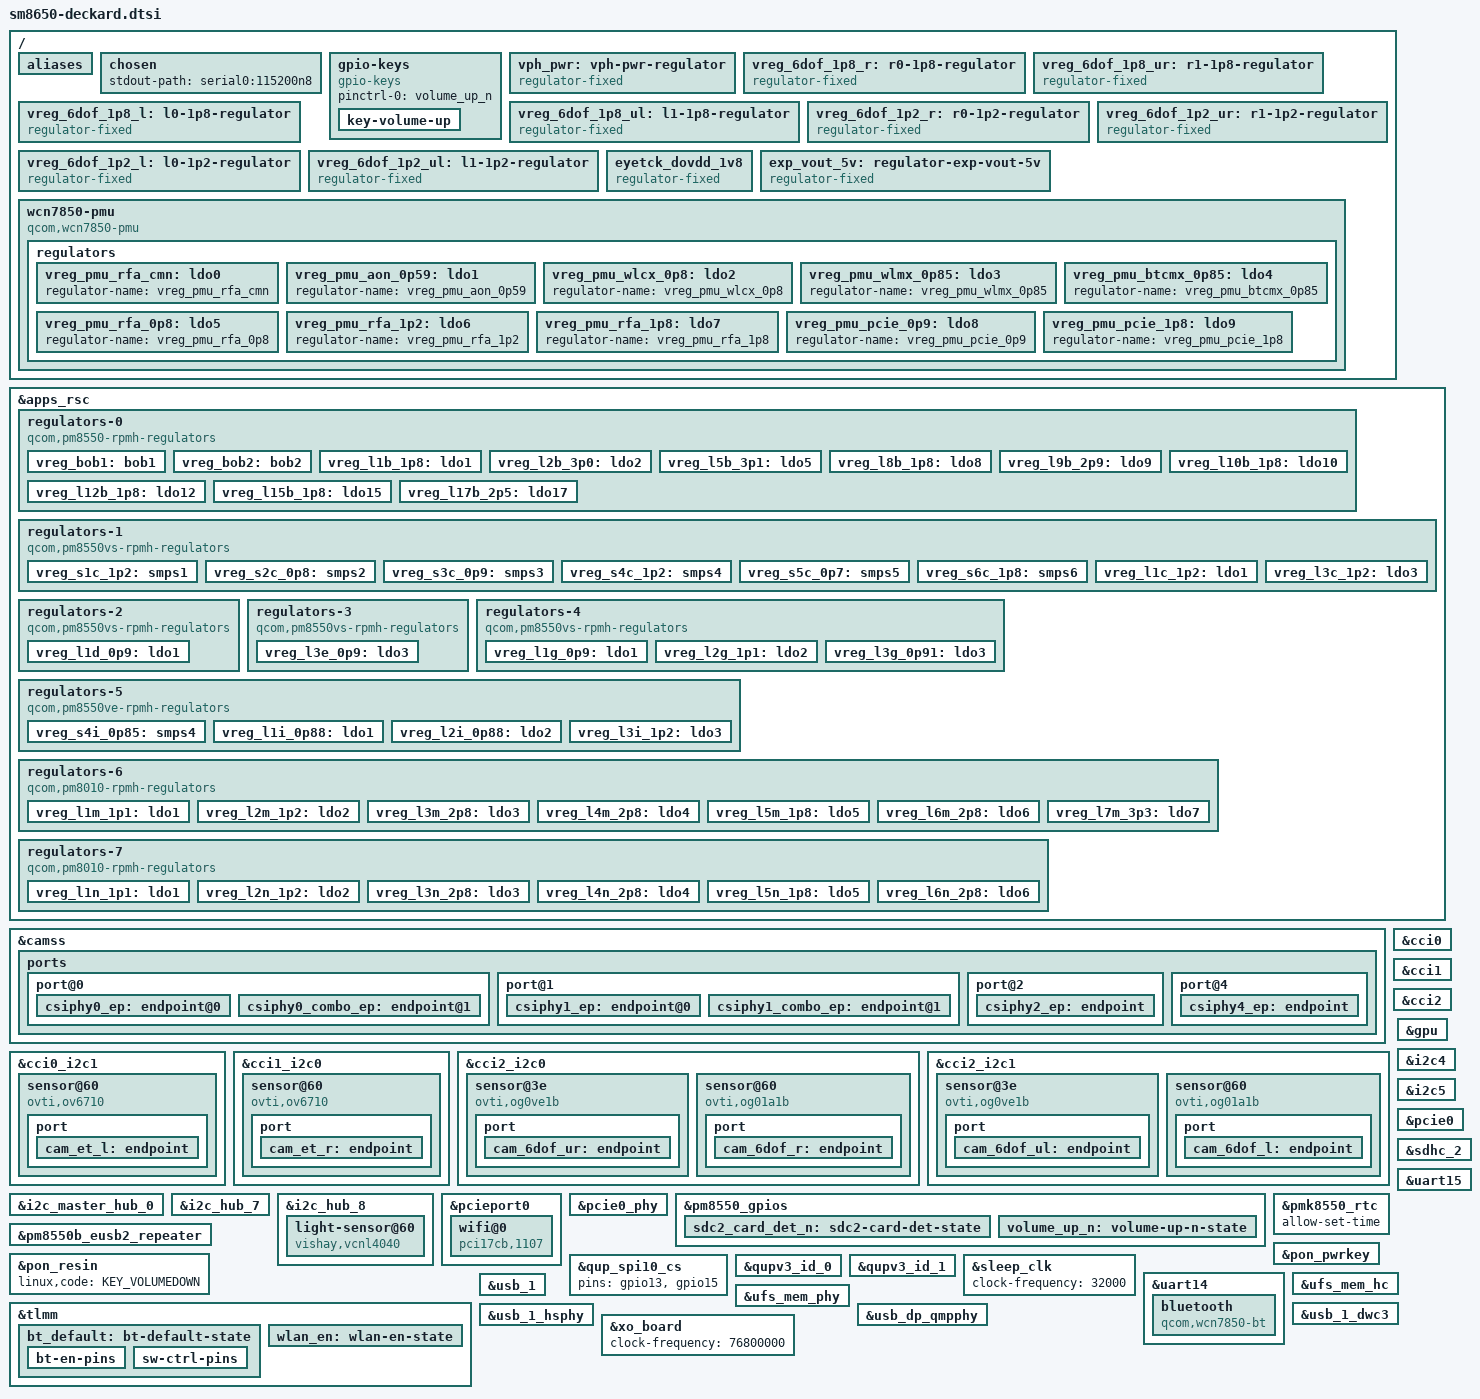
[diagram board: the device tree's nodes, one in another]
#include <dt-bindings/regulator/qcom,rpmh-regulator.h>
#include "sm8650.dtsi"
#include "pm8010.dtsi"
#include "pm8550.dtsi"
#include "pm8550b.dtsi"
#include "pm8550vs.dtsi"
#define PMK8550VE_SID 8
#include "pm8550ve.dtsi"
#include "pmk8550.dtsi"
#include "sm8650-el2.dtsi"

/ {
	aliases {
		serial0 = &uart15;
		serial1 = &uart14;
	};

	chosen {
		stdout-path = "serial0:115200n8";
	};

	gpio-keys {
		compatible = "gpio-keys";

		pinctrl-0 = <&volume_up_n>;
		pinctrl-names = "default";

		key-volume-up {
			label = "Volume Up";
			linux,code = <KEY_VOLUMEUP>;
			gpios = <&pm8550_gpios 6 GPIO_ACTIVE_LOW>;
			debounce-interval = <15>;
			linux,can-disable;
			wakeup-source;
		};
	};

	vph_pwr: vph-pwr-regulator {
		compatible = "regulator-fixed";

		regulator-name = "vph_pwr";
		regulator-min-microvolt = <3700000>;
		regulator-max-microvolt = <3700000>;

		regulator-always-on;
		regulator-boot-on;
	};

	vreg_6dof_1p8_r: r0-1p8-regulator {
		compatible = "regulator-fixed";
		regulator-name = "vreg_6dof_1p8_r";
		regulator-min-microvolt = <1800000>;
		regulator-max-microvolt = <1800000>;
		gpio = <&tlmm 36 GPIO_ACTIVE_HIGH>;
		vin-supply = <&vreg_l5m_1p8>;
		enable-active-high;
	};

	vreg_6dof_1p8_ur: r1-1p8-regulator {
		compatible = "regulator-fixed";
		regulator-name = "vreg_6dof_1p8_ur";
		regulator-min-microvolt = <1800000>;
		regulator-max-microvolt = <1800000>;
		gpio = <&tlmm 33 GPIO_ACTIVE_HIGH>;
		vin-supply = <&vreg_l5m_1p8>;
		enable-active-high;
	};

	vreg_6dof_1p8_l: l0-1p8-regulator {
		compatible = "regulator-fixed";
		regulator-name = "vreg_6dof_1p8_l";
		regulator-min-microvolt = <1800000>;
		regulator-max-microvolt = <1800000>;
		gpio = <&tlmm 36 GPIO_ACTIVE_HIGH>;
		vin-supply = <&vreg_l5n_1p8>;
		enable-active-high;
	};

	vreg_6dof_1p8_ul: l1-1p8-regulator {
		compatible = "regulator-fixed";
		regulator-name = "vreg_6dof_1p8_ul";
		regulator-min-microvolt = <1800000>;
		regulator-max-microvolt = <1800000>;
		gpio = <&tlmm 33 GPIO_ACTIVE_HIGH>;
		vin-supply = <&vreg_l5n_1p8>;
		enable-active-high;
	};

	vreg_6dof_1p2_r: r0-1p2-regulator {
		compatible = "regulator-fixed";
		regulator-name = "vreg_6dof_1p2_r";
		regulator-min-microvolt = <1200000>;
		regulator-max-microvolt = <1200000>;
		gpio = <&tlmm 37 GPIO_ACTIVE_HIGH>;
		vin-supply = <&vreg_l2m_1p2>;
		enable-active-high;
	};

	vreg_6dof_1p2_ur: r1-1p2-regulator {
		compatible = "regulator-fixed";
		regulator-name = "vreg_6dof_1p2_ur";
		regulator-min-microvolt = <1200000>;
		regulator-max-microvolt = <1200000>;
		gpio = <&tlmm 34 GPIO_ACTIVE_HIGH>;
		vin-supply = <&vreg_l2m_1p2>;
		enable-active-high;
	};

	vreg_6dof_1p2_l: l0-1p2-regulator {
		compatible = "regulator-fixed";
		regulator-name = "vreg_6dof_1p2_l";
		regulator-min-microvolt = <1200000>;
		regulator-max-microvolt = <1200000>;
		gpio = <&tlmm 37 GPIO_ACTIVE_HIGH>;
		vin-supply = <&vreg_l2n_1p2>;
		enable-active-high;
	};

	vreg_6dof_1p2_ul: l1-1p2-regulator {
		compatible = "regulator-fixed";
		regulator-name = "vreg_6dof_1p2_ul";
		regulator-min-microvolt = <1200000>;
		regulator-max-microvolt = <1200000>;
		gpio = <&tlmm 34 GPIO_ACTIVE_HIGH>;
		vin-supply = <&vreg_l2n_1p2>;
		enable-active-high;
	};

	eyetck_dovdd_1v8: eyetck_dovdd_1v8 {
		compatible = "regulator-fixed";
		regulator-name = "eyetck_dovdd_1v8";
		regulator-min-microvolt = <1800000>;
		regulator-max-microvolt = <1800000>;
		enable-active-high;
		gpio = <&tlmm 74 GPIO_ACTIVE_HIGH>;
		vin-supply = <&vreg_l5m_1p8>;
	};

	exp_vout_5v: regulator-exp-vout-5v {
		compatible = "regulator-fixed";
		regulator-name = "exp_vout_5v";
		regulator-min-microvolt = <5000000>;
		regulator-max-microvolt = <5000000>;
		gpio = <&pm8550vs_g_gpios 6 GPIO_ACTIVE_HIGH>;
		enable-active-high;
		vin-supply = <&vph_pwr>;
		regulator-always-on;
	};

	wcn7850-pmu {
		compatible = "qcom,wcn7850-pmu";

		pinctrl-names = "default";
		pinctrl-0 = <&wlan_en>, <&bt_default>;

		wlan-enable-gpios = <&tlmm 16 GPIO_ACTIVE_HIGH>;
		bt-enable-gpios = <&tlmm 17 GPIO_ACTIVE_HIGH>;

		vdd-supply = <&vreg_s4i_0p85>;
		vddio-supply = <&vreg_l15b_1p8>;
		vddio1p2-supply = <&vreg_l3c_1p2>;
		vddaon-supply = <&vreg_s2c_0p8>;
		vdddig-supply = <&vreg_s3c_0p9>;
		vddrfa1p2-supply = <&vreg_s1c_1p2>;
		vddrfa1p8-supply = <&vreg_s6c_1p8>;

		clocks = <&rpmhcc RPMH_RF_CLK1>;

		regulators {
			vreg_pmu_rfa_cmn: ldo0 {
				regulator-name = "vreg_pmu_rfa_cmn";
			};

			vreg_pmu_aon_0p59: ldo1 {
				regulator-name = "vreg_pmu_aon_0p59";
			};

			vreg_pmu_wlcx_0p8: ldo2 {
				regulator-name = "vreg_pmu_wlcx_0p8";
			};

			vreg_pmu_wlmx_0p85: ldo3 {
				regulator-name = "vreg_pmu_wlmx_0p85";
			};

			vreg_pmu_btcmx_0p85: ldo4 {
				regulator-name = "vreg_pmu_btcmx_0p85";
			};

			vreg_pmu_rfa_0p8: ldo5 {
				regulator-name = "vreg_pmu_rfa_0p8";
			};

			vreg_pmu_rfa_1p2: ldo6 {
				regulator-name = "vreg_pmu_rfa_1p2";
			};

			vreg_pmu_rfa_1p8: ldo7 {
				regulator-name = "vreg_pmu_rfa_1p8";
			};

			vreg_pmu_pcie_0p9: ldo8 {
				regulator-name = "vreg_pmu_pcie_0p9";
			};

			vreg_pmu_pcie_1p8: ldo9 {
				regulator-name = "vreg_pmu_pcie_1p8";
			};
		};
	};
};

&apps_rsc {
	regulators-0 {
		compatible = "qcom,pm8550-rpmh-regulators";

		vdd-bob1-supply = <&vph_pwr>;
		vdd-bob2-supply = <&vph_pwr>;
		vdd-l1-l4-l10-supply = <&vreg_s6c_1p8>;
		vdd-l2-l13-l14-supply = <&vreg_bob1>;
		vdd-l3-supply = <&vreg_s1c_1p2>;
		vdd-l5-l16-supply = <&vreg_bob1>;
		vdd-l8-l9-supply = <&vreg_bob1>;
		vdd-l12-supply = <&vreg_s6c_1p8>;
		vdd-l15-supply = <&vreg_s6c_1p8>;
		vdd-l17-supply = <&vreg_bob2>;

		qcom,pmic-id = "b";

		vreg_bob1: bob1 {
			regulator-name = "vreg_bob1";
			regulator-min-microvolt = <3296000>; // note: min is 3008000, init is 3296000
			regulator-max-microvolt = <3960000>;
			regulator-initial-mode = <RPMH_REGULATOR_MODE_HPM>;
		};

		vreg_bob2: bob2 {
			regulator-name = "vreg_bob2";
			regulator-min-microvolt = <2720000>; // note: min is 2704000, init is 2720000
			regulator-max-microvolt = <3008000>;
			regulator-initial-mode = <RPMH_REGULATOR_MODE_HPM>;

			regulator-always-on; // XXX USB HS, SBU MUX
		};

		vreg_l1b_1p8: ldo1 {
			regulator-name = "vreg_l1b_1p8";
			regulator-min-microvolt = <1800000>;
			regulator-max-microvolt = <1800000>;
			regulator-initial-mode = <RPMH_REGULATOR_MODE_HPM>;

			regulator-always-on; // XXX sensors
		};

		vreg_l2b_3p0: ldo2 {
			regulator-name = "vreg_l2b_3p0";
			regulator-min-microvolt = <3008000>;
			regulator-max-microvolt = <3008000>;
			regulator-initial-mode = <RPMH_REGULATOR_MODE_HPM>;

			regulator-always-on; // XXX sensors
		};

		vreg_l5b_3p1: ldo5 {
			regulator-name = "vreg_l5b_3p1";
			regulator-min-microvolt = <3104000>;
			regulator-max-microvolt = <3104000>;
			regulator-initial-mode = <RPMH_REGULATOR_MODE_HPM>;
			regulator-allow-set-load;
			regulator-allowed-modes = <RPMH_REGULATOR_MODE_LPM
						   RPMH_REGULATOR_MODE_HPM>;
			regulator-always-on; // XXX SBU MUX
		};

		vreg_l8b_1p8: ldo8 {
			regulator-name = "vreg_l8b_1p8";
			regulator-min-microvolt = <1800000>;
			regulator-max-microvolt = <1800000>;
			regulator-initial-mode = <RPMH_REGULATOR_MODE_HPM>;
			regulator-allow-set-load;
			regulator-allowed-modes = <RPMH_REGULATOR_MODE_LPM
						   RPMH_REGULATOR_MODE_HPM>;
		};

		vreg_l9b_2p9: ldo9 {
			regulator-name = "vreg_l9b_2p9";
			regulator-min-microvolt = <2960000>;
			regulator-max-microvolt = <2960000>;
			regulator-initial-mode = <RPMH_REGULATOR_MODE_HPM>;
			regulator-allow-set-load;
			regulator-allowed-modes = <RPMH_REGULATOR_MODE_LPM
						   RPMH_REGULATOR_MODE_HPM>;
		};

		vreg_l10b_1p8: ldo10 {
			regulator-name = "vreg_l10b_1p8";
			regulator-min-microvolt = <1800000>;
			regulator-max-microvolt = <1800000>;
			regulator-initial-mode = <RPMH_REGULATOR_MODE_HPM>;

			regulator-always-on; // XXX DMIC
		};

		vreg_l12b_1p8: ldo12 {
			regulator-name = "vreg_l12b_1p8";
			regulator-min-microvolt = <1800000>;
			regulator-max-microvolt = <1800000>;
			regulator-initial-mode = <RPMH_REGULATOR_MODE_HPM>;
			regulator-allow-set-load;
			regulator-allowed-modes = <RPMH_REGULATOR_MODE_LPM
						   RPMH_REGULATOR_MODE_HPM>;
		};

		vreg_l15b_1p8: ldo15 {
			regulator-name = "vreg_l15b_1p8";
			regulator-min-microvolt = <1800000>;
			regulator-max-microvolt = <1800000>;
			regulator-initial-mode = <RPMH_REGULATOR_MODE_HPM>;
			regulator-allow-set-load;
			regulator-allowed-modes = <RPMH_REGULATOR_MODE_LPM
						   RPMH_REGULATOR_MODE_HPM>;
			regulator-always-on; // XXX: 1.8V pull ups
		};

		vreg_l17b_2p5: ldo17 {
			regulator-name = "vreg_l17b_2p5";
			regulator-min-microvolt = <2504000>;
			regulator-max-microvolt = <2504000>;
			regulator-initial-mode = <RPMH_REGULATOR_MODE_HPM>;
			regulator-allow-set-load;
			regulator-allowed-modes = <RPMH_REGULATOR_MODE_LPM
						   RPMH_REGULATOR_MODE_HPM>;
		};
	};

	regulators-1 {
		compatible = "qcom,pm8550vs-rpmh-regulators";

		vdd-l1-supply = <&vreg_s1c_1p2>;
		vdd-l3-supply = <&vreg_s1c_1p2>;
		vdd-s1-supply = <&vph_pwr>;
		vdd-s2-supply = <&vph_pwr>;
		vdd-s3-supply = <&vph_pwr>;
		vdd-s4-supply = <&vph_pwr>;
		vdd-s5-supply = <&vph_pwr>;
		vdd-s6-supply = <&vph_pwr>;

		qcom,pmic-id = "c";

		vreg_s1c_1p2: smps1 {
			regulator-name = "vreg_s1c_1p2";
			regulator-min-microvolt = <1224000>;
			regulator-max-microvolt = <1348000>;
			// init 1256000
			regulator-initial-mode = <RPMH_REGULATOR_MODE_HPM>;

			regulator-always-on; // USB, UFS?
		};

		vreg_s2c_0p8: smps2 {
			regulator-name = "vreg_s2c_0p8";
			regulator-min-microvolt = <500000>;
			regulator-max-microvolt = <1036000>;
			// init 852000
			regulator-initial-mode = <RPMH_REGULATOR_MODE_HPM>;
		};

		vreg_s3c_0p9: smps3 {
			regulator-name = "vreg_s3c_0p9";
			regulator-min-microvolt = <904000>;
			regulator-max-microvolt = <1064000>;
			// init 976000
			regulator-initial-mode = <RPMH_REGULATOR_MODE_HPM>;
		};

		vreg_s4c_1p2: smps4 {
			regulator-name = "vreg_s4c_1p2";
			regulator-min-microvolt = <1200000>;
			regulator-max-microvolt = <1280000>;
			// init 1224000
			regulator-initial-mode = <RPMH_REGULATOR_MODE_HPM>;
		};

		vreg_s5c_0p7: smps5 {
			regulator-name = "vreg_s5c_0p7";
			regulator-min-microvolt = <300000>;
			regulator-max-microvolt = <900000>;
			// init 752000
			regulator-initial-mode = <RPMH_REGULATOR_MODE_HPM>;
		};

		vreg_s6c_1p8: smps6 {
			regulator-name = "vreg_s6c_1p8";
			regulator-min-microvolt = <1856000>;
			regulator-max-microvolt = <2000000>;
			// init 1856000
			regulator-initial-mode = <RPMH_REGULATOR_MODE_HPM>;
		};

		vreg_l1c_1p2: ldo1 {
			regulator-name = "vreg_l1c_1p2";
			regulator-min-microvolt = <1200000>; // note: min 1100000
			regulator-max-microvolt = <1200000>;
			regulator-initial-mode = <RPMH_REGULATOR_MODE_HPM>;
			regulator-allow-set-load;
			regulator-allowed-modes = <RPMH_REGULATOR_MODE_LPM
						   RPMH_REGULATOR_MODE_HPM>;
		};

		vreg_l3c_1p2: ldo3 {
			regulator-name = "vreg_l3c_1p2";
			regulator-min-microvolt = <1200000>;
			regulator-max-microvolt = <1200000>;
			regulator-initial-mode = <RPMH_REGULATOR_MODE_HPM>;
			regulator-allow-set-load;
			regulator-allowed-modes = <RPMH_REGULATOR_MODE_LPM
						   RPMH_REGULATOR_MODE_HPM>;
			regulator-always-on; // XXX: 1.2V pull ups
		};
	};

	regulators-2 {
		compatible = "qcom,pm8550vs-rpmh-regulators";
		qcom,pmic-id = "d";

		vdd-l1-supply = <&vreg_s3c_0p9>;

		vreg_l1d_0p9: ldo1 {
			regulator-name = "vreg_l1d_0p9";
			regulator-min-microvolt = <912000>; // note: min 880000
			regulator-max-microvolt = <920000>;
			regulator-initial-mode = <RPMH_REGULATOR_MODE_HPM>;
			regulator-allow-set-load;
			regulator-allowed-modes = <RPMH_REGULATOR_MODE_LPM
						   RPMH_REGULATOR_MODE_HPM>;
		};
	};

	regulators-3 {
		compatible = "qcom,pm8550vs-rpmh-regulators";

		vdd-l3-supply = <&vreg_s3c_0p9>;

		qcom,pmic-id = "e";

		vreg_l3e_0p9: ldo3 {
			regulator-name = "vreg_l3e_0p9";
			regulator-min-microvolt = <880000>;
			regulator-max-microvolt = <920000>;
			regulator-initial-mode = <RPMH_REGULATOR_MODE_HPM>;
			regulator-allow-set-load;
			regulator-allowed-modes = <RPMH_REGULATOR_MODE_LPM
						   RPMH_REGULATOR_MODE_HPM>;
		};
	};

	regulators-4 {
		compatible = "qcom,pm8550vs-rpmh-regulators";

		vdd-l1-supply = <&vreg_s3c_0p9>;
		vdd-l2-supply = <&vreg_s1c_1p2>;
		vdd-l3-supply = <&vreg_s3c_0p9>;

		qcom,pmic-id = "g";

		vreg_l1g_0p9: ldo1 {
			regulator-name = "vreg_l1g_0p9";
			regulator-min-microvolt = <912000>;
			regulator-max-microvolt = <920000>;
			regulator-initial-mode = <RPMH_REGULATOR_MODE_HPM>;
			// QLINK ?
		};

		vreg_l2g_1p1: ldo2 {
			regulator-name = "vreg_l2g_1p1";
			regulator-min-microvolt = <1104000>;
			regulator-max-microvolt = <1104000>;
			regulator-initial-mode = <RPMH_REGULATOR_MODE_HPM>;
		};

		vreg_l3g_0p91: ldo3 {
			regulator-name = "vreg_l3g_0p91";
			regulator-min-microvolt = <880000>;
			regulator-max-microvolt = <912000>;
			regulator-initial-mode = <RPMH_REGULATOR_MODE_HPM>;
		};
	};

	regulators-5 {
		compatible = "qcom,pm8550ve-rpmh-regulators";

		vdd-l1-supply = <&vreg_s3c_0p9>;
		vdd-l2-supply = <&vreg_s3c_0p9>;
		vdd-l3-supply = <&vreg_s1c_1p2>;
		vdd-s4-supply = <&vph_pwr>;

		qcom,pmic-id = "i";

		vreg_s4i_0p85: smps4 {
			regulator-name = "vreg_s4i_0p85";
			regulator-min-microvolt = <852000>;
			regulator-max-microvolt = <1004000>;
			// init 852000
			regulator-initial-mode = <RPMH_REGULATOR_MODE_HPM>;
		};

		vreg_l1i_0p88: ldo1 {
			regulator-name = "vreg_l1i_0p88";
			regulator-min-microvolt = <880000>;
			regulator-max-microvolt = <912000>;
			regulator-initial-mode = <RPMH_REGULATOR_MODE_HPM>;
			regulator-allow-set-load;
			regulator-allowed-modes = <RPMH_REGULATOR_MODE_LPM
						   RPMH_REGULATOR_MODE_HPM>;
		};

		vreg_l2i_0p88: ldo2 {
			regulator-name = "vreg_l2i_0p88";
			regulator-min-microvolt = <880000>;
			regulator-max-microvolt = <912000>;
			regulator-initial-mode = <RPMH_REGULATOR_MODE_HPM>;
			regulator-allow-set-load;
			regulator-allowed-modes = <RPMH_REGULATOR_MODE_LPM
						   RPMH_REGULATOR_MODE_HPM>;
		};

		vreg_l3i_1p2: ldo3 {
			regulator-name = "vreg_l3i_1p2";
			regulator-min-microvolt = <1200000>;
			regulator-max-microvolt = <1200000>;
			regulator-initial-mode = <RPMH_REGULATOR_MODE_HPM>;
			regulator-allow-set-load;
			regulator-allowed-modes = <RPMH_REGULATOR_MODE_LPM
						   RPMH_REGULATOR_MODE_HPM>;
		};
	};

	regulators-6 {
		compatible = "qcom,pm8010-rpmh-regulators";
		qcom,pmic-id = "m";

		vdd-l1-l2-supply = <&vreg_s1c_1p2>;
		vdd-l3-l4-supply = <&vreg_bob2>;
		vdd-l5-supply = <&vreg_s6c_1p8>;
		vdd-l6-supply = <&vreg_bob1>;
		vdd-l7-supply = <&vreg_bob1>;

		vreg_l1m_1p1: ldo1 {
			regulator-name = "vreg_l1m_1p1";
			regulator-min-microvolt = <1104000>;
			regulator-max-microvolt = <1104000>;
			regulator-initial-mode = <RPMH_REGULATOR_MODE_HPM>;
			regulator-allow-set-load;
			regulator-allowed-modes = <RPMH_REGULATOR_MODE_LPM
						   RPMH_REGULATOR_MODE_HPM>;
		};

		vreg_l2m_1p2: ldo2 {
			regulator-name = "vreg_l2m_1p2";
			regulator-min-microvolt = <1200000>;
			regulator-max-microvolt = <1200000>;
			regulator-initial-mode = <RPMH_REGULATOR_MODE_HPM>;
			regulator-allow-set-load;
			regulator-allowed-modes = <RPMH_REGULATOR_MODE_LPM
						   RPMH_REGULATOR_MODE_HPM>;
		};

		vreg_l3m_2p8: ldo3 {
			regulator-name = "vreg_l3m_2p8";
			regulator-min-microvolt = <2800000>;
			regulator-max-microvolt = <2800000>;
			regulator-initial-mode = <RPMH_REGULATOR_MODE_HPM>;
		};

		vreg_l4m_2p8: ldo4 {
			regulator-name = "vreg_l4m_2p8";
			regulator-min-microvolt = <2800000>;
			regulator-max-microvolt = <2800000>;
			regulator-initial-mode = <RPMH_REGULATOR_MODE_HPM>;
		};

		vreg_l5m_1p8: ldo5 {
			regulator-name = "vreg_l5m_1p8";
			regulator-min-microvolt = <1800000>;
			regulator-max-microvolt = <1800000>;
			regulator-initial-mode = <RPMH_REGULATOR_MODE_HPM>;
		};

		vreg_l6m_2p8: ldo6 {
			regulator-name = "vreg_l6m_2p8";
			regulator-min-microvolt = <2800000>;
			regulator-max-microvolt = <2800000>;
			regulator-initial-mode = <RPMH_REGULATOR_MODE_HPM>;
		};

		vreg_l7m_3p3: ldo7 {
			regulator-name = "vreg_l7m_3p3";
			regulator-min-microvolt = <3304000>;
			regulator-max-microvolt = <3304000>;
			regulator-initial-mode = <RPMH_REGULATOR_MODE_HPM>;

			regulator-always-on;
		};
	};

	regulators-7 {
		compatible = "qcom,pm8010-rpmh-regulators";
		qcom,pmic-id = "n";

		vdd-l1-l2-supply = <&vreg_s1c_1p2>;
		vdd-l3-l4-supply = <&vreg_bob2>;
		vdd-l5-supply = <&vreg_s6c_1p8>;
		vdd-l6-supply = <&vreg_bob1>;

		vreg_l1n_1p1: ldo1 {
			regulator-name = "vreg_l1n_1p1";
			regulator-min-microvolt = <1104000>;
			regulator-max-microvolt = <1104000>;
			regulator-initial-mode = <RPMH_REGULATOR_MODE_HPM>;
			regulator-allow-set-load;
			regulator-allowed-modes = <RPMH_REGULATOR_MODE_LPM
						   RPMH_REGULATOR_MODE_HPM>;
		};

		vreg_l2n_1p2: ldo2 {
			regulator-name = "vreg_l2n_1p2";
			regulator-min-microvolt = <1200000>;
			regulator-max-microvolt = <1200000>;
			regulator-initial-mode = <RPMH_REGULATOR_MODE_HPM>;
			regulator-allow-set-load;
			regulator-allowed-modes = <RPMH_REGULATOR_MODE_LPM
						   RPMH_REGULATOR_MODE_HPM>;
		};

		vreg_l3n_2p8: ldo3 {
			regulator-name = "vreg_l3n_2p8";
			regulator-min-microvolt = <2800000>;
			regulator-max-microvolt = <2800000>;
			regulator-initial-mode = <RPMH_REGULATOR_MODE_HPM>;
		};

		vreg_l4n_2p8: ldo4 {
			regulator-name = "vreg_l4n_2p8";
			regulator-min-microvolt = <2800000>;
			regulator-max-microvolt = <2800000>;
			regulator-initial-mode = <RPMH_REGULATOR_MODE_HPM>;
		};

		vreg_l5n_1p8: ldo5 {
			regulator-name = "vreg_l5n_1p8";
			regulator-min-microvolt = <1800000>;
			regulator-max-microvolt = <1800000>;
			regulator-initial-mode = <RPMH_REGULATOR_MODE_HPM>;
		};

		vreg_l6n_2p8: ldo6 {
			regulator-name = "vreg_l6n_2p8";
			regulator-min-microvolt = <2800000>;
			regulator-max-microvolt = <2800000>;
			regulator-initial-mode = <RPMH_REGULATOR_MODE_HPM>;
		};
	};
};

&camss {
	status = "okay";

	vdda-csi01-0p9-supply = <&vreg_l2i_0p88>;
	vdda-csi01-1p2-supply = <&vreg_l3i_1p2>;
	vdda-csi24-0p9-supply = <&vreg_l2i_0p88>;
	vdda-csi24-1p2-supply = <&vreg_l3i_1p2>;

	ports {
		port@0 {
			#address-cells = <1>;
			#size-cells = <0>;

			csiphy0_ep: endpoint@0 {
				reg = <0>;
				clock-lanes = <4>;
				data-lanes = <0 1>;
				remote-endpoint = <&cam_6dof_l>;
			};

			csiphy0_combo_ep: endpoint@1 {
				reg = <1>;
				clock-lanes = <3>;
				data-lanes = <2>;
				remote-endpoint = <&cam_6dof_ul>;
			};
		};

		port@1 {
			#address-cells = <1>;
			#size-cells = <0>;

			csiphy1_ep: endpoint@0 {
				reg = <0>;
				clock-lanes = <4>;
				data-lanes = <0 1>;
				remote-endpoint = <&cam_6dof_r>;
			};

			csiphy1_combo_ep: endpoint@1 {
				reg = <1>;
				clock-lanes = <3>;
				data-lanes = <2>;
				remote-endpoint = <&cam_6dof_ur>;
			};
		};

		port@2 {
			csiphy2_ep: endpoint {
				clock-lanes = <4>;
				data-lanes = <0>;
				remote-endpoint = <&cam_et_l>;
			};
		};

		port@4 {
			csiphy4_ep: endpoint {
				clock-lanes = <4>;
				data-lanes = <0>;
				remote-endpoint = <&cam_et_r>;
			};
		};
	};
};

&cci0 {
	status = "okay";
};

&cci0_i2c1 {
	sensor@60 {
		compatible = "ovti,ov6710";
		reg = <0x60>;
		clocks = <&camcc CAM_CC_MCLK4_CLK>;
		reset-gpios = <&tlmm 7 GPIO_ACTIVE_LOW>;
		pinctrl-0 = <&cam4_default>;
		pinctrl-names = "default";
		avdd-supply = <&vreg_l6n_2p8>;
		dovdd-supply = <&eyetck_dovdd_1v8>;
		dvdd-supply = <&vreg_l1n_1p1>;

		port {
			cam_et_l: endpoint {
				data-lanes = <1>;
				link-frequencies = /bits/ 64 <240000000>;
				remote-endpoint = <&csiphy2_ep>;
			};
		};
	};
};

&cci1 {
	pinctrl-0 = <&cci1_0_default>;
	pinctrl-1 = <&cci1_0_sleep>;
	status = "okay";
};

&cci1_i2c0 {
	sensor@60 {
		compatible = "ovti,ov6710";
		reg = <0x60>;
		clocks = <&camcc CAM_CC_MCLK2_CLK>;
		reset-gpios = <&tlmm 3 GPIO_ACTIVE_LOW>;
		pinctrl-0 = <&cam2_default>;
		pinctrl-names = "default";
		avdd-supply = <&vreg_l6m_2p8>;
		dovdd-supply = <&eyetck_dovdd_1v8>;
		dvdd-supply = <&vreg_l1m_1p1>;

		port {
			cam_et_r: endpoint {
				data-lanes = <1>;
				link-frequencies = /bits/ 64 <240000000>;
				remote-endpoint = <&csiphy4_ep>;
			};
		};
	};
};

&cci2 {
	status = "okay";
};

&cci2_i2c0 {
	sensor@3e {
		compatible = "ovti,og0ve1b";
		reg = <0x3e>;
		clocks = <&camcc CAM_CC_MCLK5_CLK>;
		reset-gpios = <&pm8550vs_c_gpios 6 GPIO_ACTIVE_LOW>;
		strobe-gpios = <&tlmm 99 GPIO_ACTIVE_HIGH>;
		pinctrl-0 = <&cam5_default>;
		pinctrl-names = "default";
		avdd-supply = <&vreg_l4m_2p8>;
		dovdd-supply = <&vreg_6dof_1p8_ur>;
		dvdd-supply = <&vreg_6dof_1p2_ur>;

		port {
			cam_6dof_ur: endpoint {
				data-lanes = <1>;
				link-frequencies = /bits/ 64 <500000000>;
				remote-endpoint = <&csiphy1_combo_ep>;
			};
		};
	};

	sensor@60 {
		compatible = "ovti,og01a1b";
		reg = <0x60>;
		clocks = <&camcc CAM_CC_MCLK0_CLK>;
		reset-gpios = <&pm8550vs_e_gpios 4 GPIO_ACTIVE_LOW>;
		strobe-gpios = <&tlmm 121 GPIO_ACTIVE_HIGH>;
		pinctrl-0 = <&cam0_default>;
		pinctrl-names = "default";
		avdd-supply = <&vreg_l3m_2p8>;
		dovdd-supply = <&vreg_6dof_1p8_r>;
		dvdd-supply = <&vreg_6dof_1p2_r>;

		port {
			cam_6dof_r: endpoint {
				data-lanes = <1 2>;
				link-frequencies = /bits/ 64 <500000000>;
				remote-endpoint = <&csiphy1_ep>;
			};
		};
	};
};

&cci2_i2c1 {
	sensor@3e {
		compatible = "ovti,og0ve1b";
		reg = <0x3e>;
		clocks = <&camcc CAM_CC_MCLK3_CLK>;
		reset-gpios = <&pm8550vs_c_gpios 5 GPIO_ACTIVE_LOW>;
		strobe-gpios = <&tlmm 97 GPIO_ACTIVE_HIGH>;
		pinctrl-0 = <&cam3_default>;
		pinctrl-names = "default";
		avdd-supply = <&vreg_l4n_2p8>;
		dovdd-supply = <&vreg_6dof_1p8_ul>;
		dvdd-supply = <&vreg_6dof_1p2_ul>;

		port {
			cam_6dof_ul: endpoint {
				data-lanes = <1>;
				link-frequencies = /bits/ 64 <500000000>;
				remote-endpoint = <&csiphy0_combo_ep>;
			};
		};
	};

	sensor@60 {
		compatible = "ovti,og01a1b";
		reg = <0x60>;
		clocks = <&camcc CAM_CC_MCLK1_CLK>;
		reset-gpios = <&pm8550vs_e_gpios 6 GPIO_ACTIVE_LOW>;
		strobe-gpios = <&tlmm 123 GPIO_ACTIVE_HIGH>;
		ircontrol-gpios = <&tlmm 200 GPIO_ACTIVE_HIGH>;
		pinctrl-0 = <&cam1_default>;
		pinctrl-names = "default";
		avdd-supply = <&vreg_l3n_2p8>;
		dovdd-supply = <&vreg_6dof_1p8_l>;
		dvdd-supply = <&vreg_6dof_1p2_l>;

		port {
			cam_6dof_l: endpoint {
				data-lanes = <1 2>;
				link-frequencies = /bits/ 64 <500000000>;
				remote-endpoint = <&csiphy0_ep>;
			};
		};
	};
};

&gpu {
	status = "okay";
};

&i2c4 {
	status = "okay";
};

&i2c5 {
	status = "okay";
};

// Master Hub required for Hub 7 and 8
&i2c_master_hub_0 {
	status = "okay";
};

// Custom Connector I2C
&i2c_hub_7 {
	status = "okay";
};

// Prox Sensor I2C
&i2c_hub_8 {
	status = "okay";

	light-sensor@60 {
		compatible = "vishay,vcnl4040";
		reg = <0x60>;
		proximity-near-level = <220>;
		// interrupts-extended = <&tlmm 31 IRQ_TYPE_EDGE_FALLING>;
		// driver lacks support for regulators, l8c and l11c set to always on

		vin0-supply = <&vreg_l2b_3p0>; 
		vin1-supply = <&vreg_l15b_1p8>; 

		status = "okay";
	};
};

&pcie0 {
	wake-gpios = <&tlmm 96 GPIO_ACTIVE_HIGH>;
	perst-gpios = <&tlmm 94 GPIO_ACTIVE_LOW>;

	pinctrl-0 = <&pcie0_default_state>;
	pinctrl-names = "default";

	status = "okay";
};

&pcieport0 {
	wifi@0 {
		compatible = "pci17cb,1107";
		reg = <0x10000 0x0 0x0 0x0 0x0>;

		vddrfacmn-supply = <&vreg_pmu_rfa_cmn>;
		vddaon-supply = <&vreg_pmu_aon_0p59>;
		vddwlcx-supply = <&vreg_pmu_wlcx_0p8>;
		vddwlmx-supply = <&vreg_pmu_wlmx_0p85>;
		vddrfa0p8-supply = <&vreg_pmu_rfa_0p8>;
		vddrfa1p2-supply = <&vreg_pmu_rfa_1p2>;
		vddrfa1p8-supply = <&vreg_pmu_rfa_1p8>;
		vddpcie0p9-supply = <&vreg_pmu_pcie_0p9>;
		vddpcie1p8-supply = <&vreg_pmu_pcie_1p8>;
	};
};

&pcie0_phy {
	vdda-phy-supply = <&vreg_l1i_0p88>;
	vdda-pll-supply = <&vreg_l3i_1p2>;

	status = "okay";
};

&pm8550_gpios {
	sdc2_card_det_n: sdc2-card-det-state {
		pins = "gpio12";
		function = "normal";
		bias-pull-up;
		input-enable;
		output-disable;
		power-source = <1>; /* 1.8 V */
	};

	volume_up_n: volume-up-n-state {
		pins = "gpio6";
		function = "normal";
		bias-pull-up;
		input-enable;
		power-source = <1>;
	};
};

&pm8550b_eusb2_repeater {
	vdd18-supply = <&vreg_l15b_1p8>;
	vdd3-supply = <&vreg_l5b_3p1>;
};

&pmk8550_rtc {
	status = "okay";
	allow-set-time;
};

&pon_pwrkey {
	status = "okay";
};

&pon_resin {
	linux,code = <KEY_VOLUMEDOWN>;

	status = "okay";
};

&qup_spi10_cs {
	pins = "gpio13", "gpio15";
};

&qupv3_id_0 {
	status = "okay";
};

&qupv3_id_1 {
	status = "okay";
};

&sdhc_2 {
	cd-gpios = <&pm8550_gpios 12 GPIO_ACTIVE_LOW>;

	vmmc-supply = <&vreg_l9b_2p9>;
	vqmmc-supply = <&vreg_l8b_1p8>; // actually level shifter
	bus-width = <4>;
	no-sdio;
	no-mmc;

	pinctrl-0 = <&sdc2_default>, <&sdc2_card_det_n>;
	pinctrl-1 = <&sdc2_sleep>, <&sdc2_card_det_n>;
	pinctrl-names = "default", "sleep";

	status = "okay";
};

&sleep_clk {
	clock-frequency = <32000>;
};

&uart14 {
	status = "okay";

	bluetooth {
		compatible = "qcom,wcn7850-bt";

		vddrfacmn-supply = <&vreg_pmu_rfa_cmn>;
		vddaon-supply = <&vreg_pmu_aon_0p59>;
		vddwlcx-supply = <&vreg_pmu_wlcx_0p8>;
		vddwlmx-supply = <&vreg_pmu_wlmx_0p85>;
		vddrfa0p8-supply = <&vreg_pmu_rfa_0p8>;
		vddrfa1p2-supply = <&vreg_pmu_rfa_1p2>;
		vddrfa1p8-supply = <&vreg_pmu_rfa_1p8>;

		max-speed = <3200000>;
	};
};

&uart15 {
	status = "okay";
};

&tlmm {
	bt_default: bt-default-state {
		bt-en-pins {
			pins = "gpio17";
			function = "gpio";
			drive-strength = <16>;
			bias-disable;
		};

		sw-ctrl-pins {
			pins = "gpio18";
			function = "gpio";
			bias-pull-down;
		};
	};

	wlan_en: wlan-en-state {
		pins = "gpio16";
		function = "gpio";
		drive-strength = <8>;
		bias-pull-down;
	};
};

&ufs_mem_hc {
	reset-gpios = <&tlmm 210 GPIO_ACTIVE_LOW>;

	vcc-supply = <&vreg_l17b_2p5>;
	vcc-max-microamp = <1300000>;
	vccq-supply = <&vreg_l1c_1p2>;
	vccq-max-microamp = <1200000>;

	status = "okay";
};

&ufs_mem_phy {
	vdda-phy-supply = <&vreg_l1d_0p9>;
	vdda-pll-supply = <&vreg_l3i_1p2>;

	status = "okay";
};

&usb_1 {
	status = "okay";
};

&usb_1_dwc3 {
	dr_mode = "otg";
	usb-role-switch;
};


&usb_1_hsphy {
	vdd-supply = <&vreg_l1i_0p88>;
	vdda12-supply = <&vreg_l3i_1p2>;

	phys = <&pm8550b_eusb2_repeater>;

	status = "okay";
};

&usb_dp_qmpphy {
	vdda-phy-supply = <&vreg_l3i_1p2>;
	vdda-pll-supply = <&vreg_l3g_0p91>;

	orientation-switch;

	status = "okay";
};

&xo_board {
	clock-frequency = <76800000>;
};
